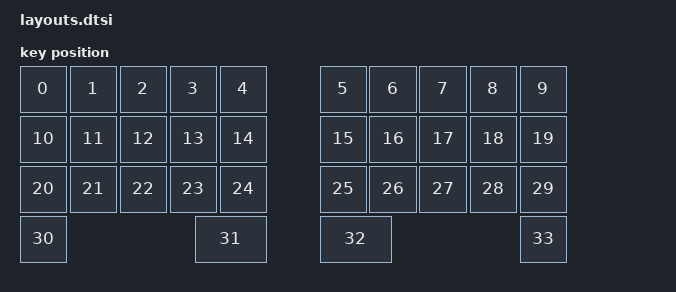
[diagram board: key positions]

#include <physical_layouts.dtsi>
/ {
    physical_layout0: physical_layout0 {
        compatible = "zmk,physical-layout";
        display-name = "Layout";
        keys
            = <&key_physical_attrs 100 100 150 200 (-9000) 150 200>
			,<&key_physical_attrs 100 100 250 200 (-9000) 250 200>
			,<&key_physical_attrs 100 100 350 200 (-9000) 350 200>
			,<&key_physical_attrs 100 100 450 200 (-9000) 450 200>
			,<&key_physical_attrs 100 100 550 200 (-9000) 550 200>
			,<&key_physical_attrs 100 100 850 100 9000 850 100>
			,<&key_physical_attrs 100 100 950 100 9000 950 100>
			,<&key_physical_attrs 100 100 1050 100 9000 1050 100>
			,<&key_physical_attrs 100 100 1150 100 9000 1150 100>
			,<&key_physical_attrs 100 100 1250 100 9000 1250 100>
			,<&key_physical_attrs 100 100 150 200 0 0 0>
			,<&key_physical_attrs 100 100 250 200 0 0 0>
			,<&key_physical_attrs 100 100 350 200 0 0 0>
			,<&key_physical_attrs 100 100 450 200 0 0 0>
			,<&key_physical_attrs 100 100 550 200 0 0 0>
			,<&key_physical_attrs 100 100 750 200 0 0 0>
			,<&key_physical_attrs 100 100 850 200 0 0 0>
			,<&key_physical_attrs 100 100 950 200 0 0 0>
			,<&key_physical_attrs 100 100 1050 200 0 0 0>
			,<&key_physical_attrs 100 100 1150 200 0 0 0>
			,<&key_physical_attrs 100 100 150 300 0 0 0>
			,<&key_physical_attrs 100 100 250 300 0 0 0>
			,<&key_physical_attrs 100 100 350 300 0 0 0>
			,<&key_physical_attrs 100 100 450 300 0 0 0>
			,<&key_physical_attrs 100 100 550 300 0 0 0>
			,<&key_physical_attrs 100 100 750 300 0 0 0>
			,<&key_physical_attrs 100 100 850 300 0 0 0>
			,<&key_physical_attrs 100 100 950 300 0 0 0>
			,<&key_physical_attrs 100 100 1050 300 0 0 0>
			,<&key_physical_attrs 100 100 1150 300 0 0 0>
			,<&key_physical_attrs 100 100 150 400 0 0 0>
			,<&key_physical_attrs 150 100 500 400 0 0 0>
			,<&key_physical_attrs 150 100 750 400 0 0 0>
			,<&key_physical_attrs 100 100 1150 400 0 0 0>
            ;
    };
};
    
